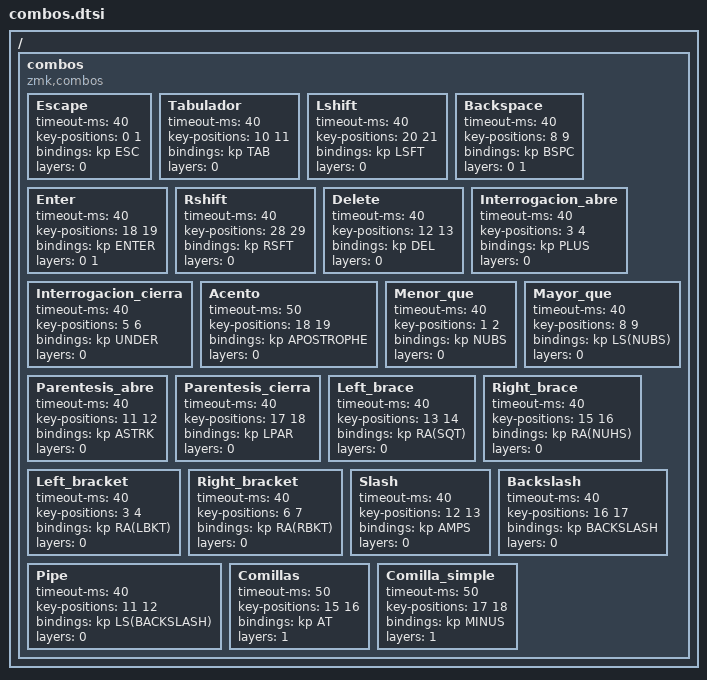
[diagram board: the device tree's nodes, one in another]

 / {
    combos {
        compatible = "zmk,combos";
        //Mods

        Escape {
            timeout-ms = <40>;
            key-positions = <0 1>; // Q y W
            bindings = <&kp ESC>;
            layers = <0>;
        };

        Tabulador {
            timeout-ms = <40>;
            key-positions = <10 11>; // A y S
            bindings = <&kp TAB>;
            layers = <0>;
        };

        Lshift {
            timeout-ms = <40>;
            key-positions = <20 21>; // Z y X
            bindings = <&kp LSFT>;
            layers = <0>;
        };

        Backspace {
            timeout-ms = <40>;
            key-positions = <8 9>; // P y +
            bindings = <&kp BSPC>;
            layers = <0 1>;
        };

        Enter {
            timeout-ms = <40>;
            key-positions = <18 19>; // L y Ñ
            bindings = <&kp ENTER>;
            layers = <0 1>;
        };

        Rshift {
            timeout-ms = <40>;
            key-positions = <28 29>; // . y -
            bindings = <&kp RSFT>;
            layers = <0>;
        };


        Delete {
            timeout-ms = <40>;
            key-positions = <12 13>; // Q y A
            bindings = <&kp DEL>;
            layers = <0>;
        };

        //symbols

        Interrogacion_abre {
            timeout-ms = <40>;
            key-positions = <3 4>; // R y T
            bindings = <&kp PLUS>; 
            layers = <0>;
        };

        Interrogacion_cierra {
            timeout-ms = <40>;
            key-positions = <5 6>; // Y y U
            bindings = <&kp UNDER>; 
            layers = <0>;
        };

        Acento {
            timeout-ms = <50>;
            key-positions = <18 19>; // K y L
            bindings = <&kp APOSTROPHE>;
            layers = <0>;
        };

        Menor_que {
            timeout-ms = <40>;
            key-positions = <1 2>; // W y E
            bindings = <&kp NUBS>;
            layers = <0>;
        };

        Mayor_que {
            timeout-ms = <40>;
            key-positions = <8 9>; // I y O
            bindings = <&kp LS(NUBS)>;
            layers = <0>;
        };

        Parentesis_abre {
            timeout-ms = <40>;
            key-positions = <11 12>; // S y D
            bindings = <&kp ASTRK>;
            layers = <0>;
        };

         Parentesis_cierra {
            timeout-ms = <40>;
            key-positions = <17 18>; // K y L
            bindings = <&kp LPAR>;
            layers = <0>;
        };

        Left_brace {
            timeout-ms = <40>;
            key-positions = <13 14>; // F y G
            bindings = <&kp RA(SQT)>;
            layers = <0>;
        };

         Right_brace {
            timeout-ms = <40>;
            key-positions = <15 16>; // H y J
            bindings = <&kp RA(NUHS)>;
            layers = <0>;
        };

        Left_bracket {
            timeout-ms = <40>;
            key-positions = <3 4>; // R y T
            bindings = <&kp RA(LBKT)>; 
            layers = <0>;
        };

        Right_bracket {
            timeout-ms = <40>;
            key-positions = <6 7>; // Y y U
            bindings = <&kp RA(RBKT)>; 
            layers = <0>;
        };
         Slash {
            timeout-ms = <40>;
            key-positions = <12 13>; // W y E
            bindings = <&kp AMPS>;
            layers = <0>;
        };

        Backslash {
            timeout-ms = <40>;
            key-positions = <16 17>; // I y O
            bindings = <&kp BACKSLASH>;
            layers = <0>;
        };
        Pipe {
            timeout-ms = <40>;
            key-positions = <11 12>; // S y D
            bindings = <&kp LS(BACKSLASH)>;
            layers = <0>;
        };
        Comillas {
            timeout-ms = <50>;
            key-positions = <15 16>; // H y J
            bindings = <&kp AT>;
            layers = <1>;
        };
         Comilla_simple {
            timeout-ms = <50>;
            key-positions = <17 18>; // K y L
            bindings = <&kp MINUS>;
            layers = <1>;
        };
    };
};
